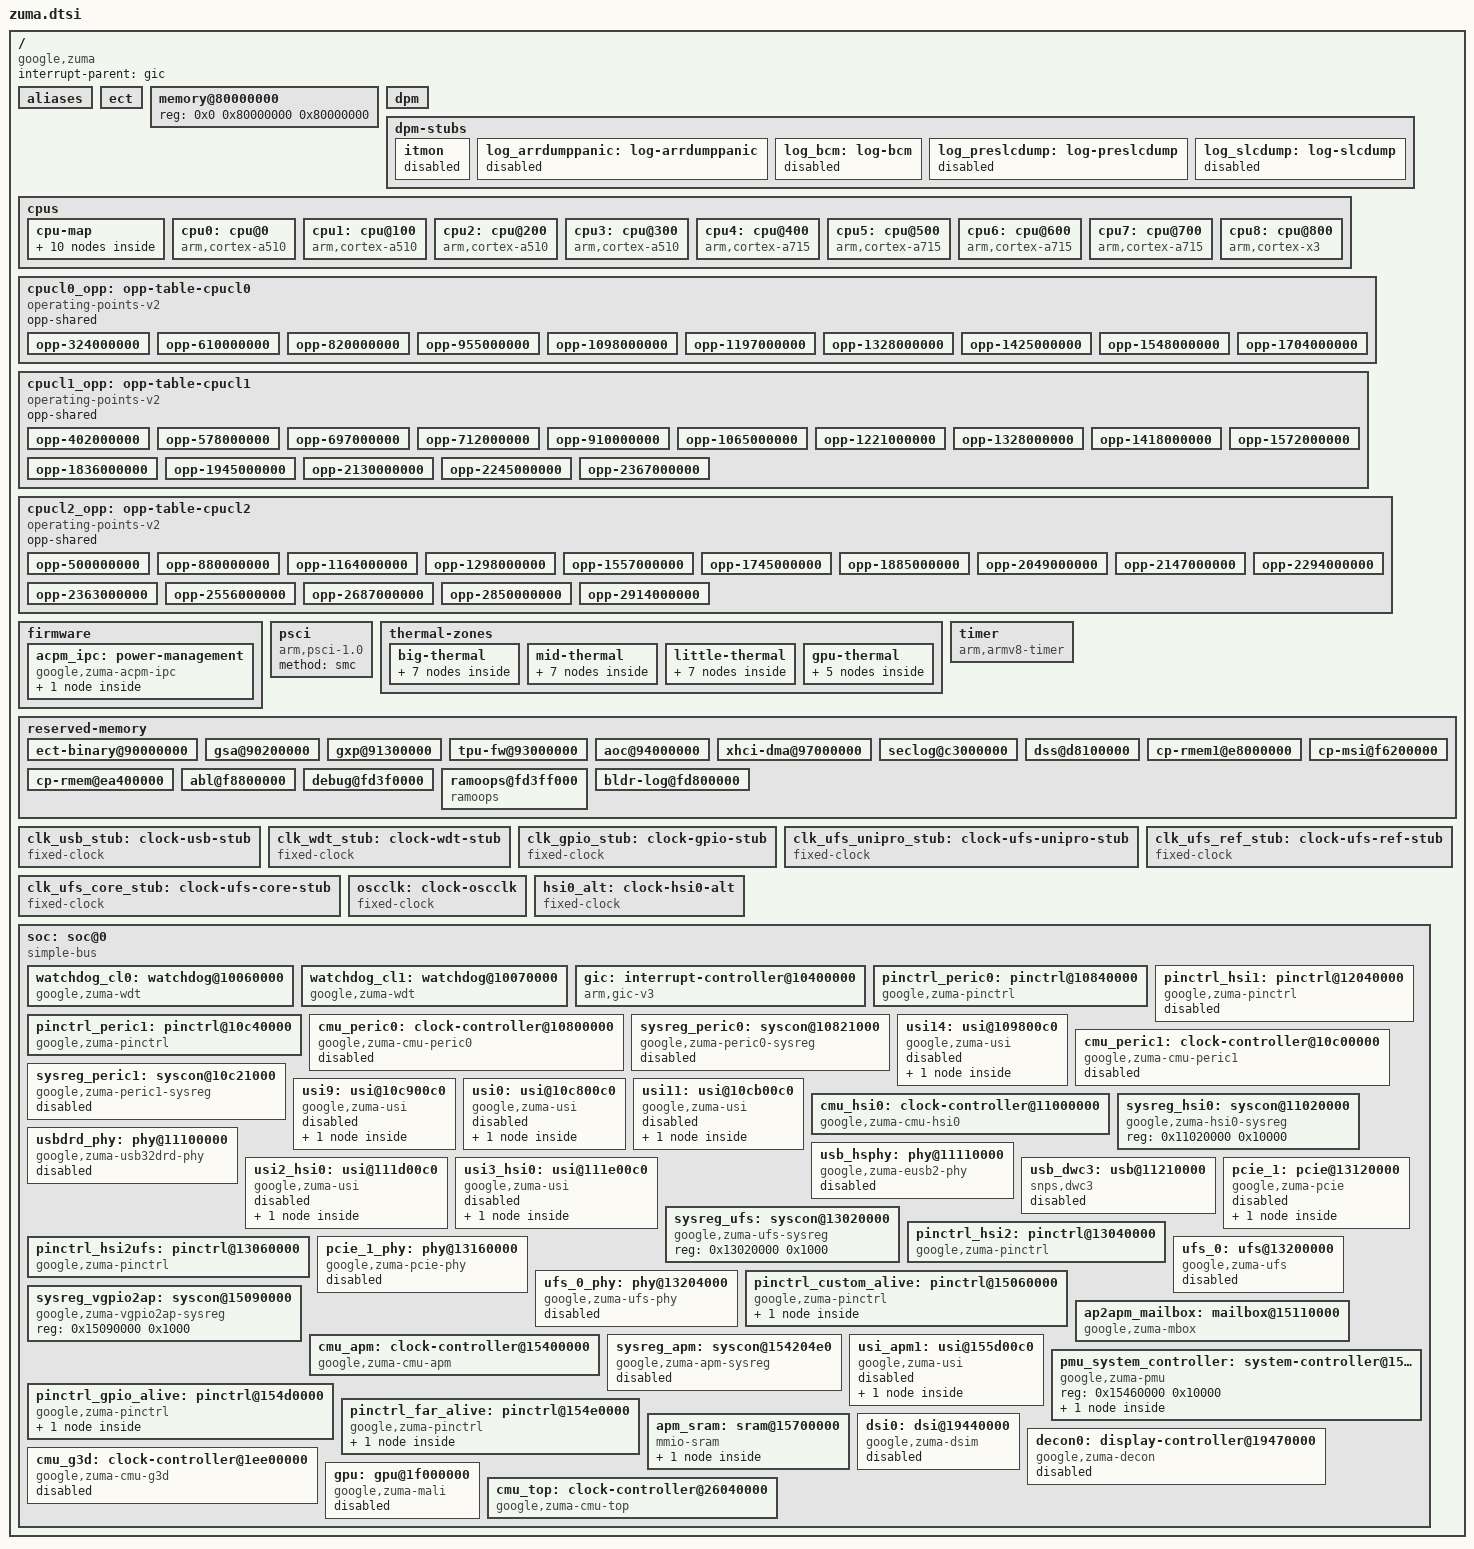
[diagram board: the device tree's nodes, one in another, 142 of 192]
// SPDX-License-Identifier: GPL-2.0-only
/*
 * Google Zuma (Tensor G3) SoC - minimal description for first light.
 *
 * Addresses, interrupts and reservations are the ones a retail Pixel 8 Pro
 * (husky) runs with: its live device tree and Google's GPL zuma tree
 * (android-gs-shusky-6.1-android16). Nothing here is copied from gs101 or
 * gs201. The clock providers describe only the touchscreen SPI's path, and
 * there are no power-domain providers yet: the bootloader leaves what the
 * rest needs running, and the board's bootargs carry clk_ignore_unused and
 * pd_ignore_unused.
 */

#include <dt-bindings/clock/google,zuma.h>
#include <dt-bindings/clock/google,zuma-acpm.h>
#include <dt-bindings/gpio/gpio.h>
#include <dt-bindings/interrupt-controller/arm-gic.h>
#include <dt-bindings/interrupt-controller/irq.h>
#include <dt-bindings/soc/samsung,exynos-usi.h>

/ {
	compatible = "google,zuma";
	#address-cells = <2>;
	#size-cells = <1>;
	interrupt-parent = <&gic>;

	/* The pin controllers are numbered as in Tensor G4's driver data. */
	aliases {
		pinctrl0 = &pinctrl_gpio_alive;
		pinctrl1 = &pinctrl_custom_alive;
		pinctrl2 = &pinctrl_far_alive;
		pinctrl8 = &pinctrl_hsi1;
		pinctrl9 = &pinctrl_hsi2;
		pinctrl10 = &pinctrl_hsi2ufs;
		pinctrl11 = &pinctrl_peric0;
		pinctrl12 = &pinctrl_peric1;
	};

	/*
	 * Required by the Pixel bootloader (ABL). zuma's stock base DTB
	 * carries the ECT location here rather than an empty node.
	 */
	ect {
		parameter_address = <0x90000000>;
		parameter_size = <0x53000>;
	};

	/*
	 * Stock's base DTB has the first DRAM bank; ABL adds the others
	 * and may update this node rather than create one.
	 */
	memory@80000000 {
		device_type = "memory";
		reg = <0x0 0x80000000 0x80000000>;
	};

	/* Target of the ABL-applied debug-policy (dpm partition) overlay. */
	dpm: dpm { };

	/*
	 * Labels the user-build debug-policy overlay targets besides &dpm
	 * (Google zuma-dpm-user.dtsi): stubs, so it applies to this tree.
	 */
	dpm-stubs {
		itmon: itmon { status = "disabled"; };
		log_arrdumppanic: log-arrdumppanic { status = "disabled"; };
		log_bcm: log-bcm { status = "disabled"; };
		log_preslcdump: log-preslcdump { status = "disabled"; };
		log_slcdump: log-slcdump { status = "disabled"; };
	};

	cpus {
		#address-cells = <1>;
		#size-cells = <0>;

		cpu-map {
			cluster0 {
				core0 { cpu = <&cpu0>; };
				core1 { cpu = <&cpu1>; };
				core2 { cpu = <&cpu2>; };
				core3 { cpu = <&cpu3>; };
				core4 { cpu = <&cpu4>; };
				core5 { cpu = <&cpu5>; };
				core6 { cpu = <&cpu6>; };
				core7 { cpu = <&cpu7>; };
				core8 { cpu = <&cpu8>; };
			};
		};

		/*
		 * Four Cortex-A510, four Cortex-A715 and one Cortex-X3 (MIDR
		 * parts 0xd46, 0xd4d, 0xd4e). Capacities are stock's.
		 */
		cpu0: cpu@0 {
			device_type = "cpu";
			compatible = "arm,cortex-a510";
			reg = <0x000>;
			enable-method = "psci";
			capacity-dmips-mhz = <193>;
			#cooling-cells = <2>;
			clocks = <&acpm_ipc ZUMA_CLK_ACPM_DVFS_CPUCL0>;
		};
		cpu1: cpu@100 {
			device_type = "cpu";
			compatible = "arm,cortex-a510";
			reg = <0x100>;
			enable-method = "psci";
			capacity-dmips-mhz = <193>;
			#cooling-cells = <2>;
			clocks = <&acpm_ipc ZUMA_CLK_ACPM_DVFS_CPUCL0>;
		};
		cpu2: cpu@200 {
			device_type = "cpu";
			compatible = "arm,cortex-a510";
			reg = <0x200>;
			enable-method = "psci";
			capacity-dmips-mhz = <193>;
			#cooling-cells = <2>;
			clocks = <&acpm_ipc ZUMA_CLK_ACPM_DVFS_CPUCL0>;
		};
		cpu3: cpu@300 {
			device_type = "cpu";
			compatible = "arm,cortex-a510";
			reg = <0x300>;
			enable-method = "psci";
			capacity-dmips-mhz = <193>;
			#cooling-cells = <2>;
			clocks = <&acpm_ipc ZUMA_CLK_ACPM_DVFS_CPUCL0>;
		};
		cpu4: cpu@400 {
			device_type = "cpu";
			compatible = "arm,cortex-a715";
			reg = <0x400>;
			enable-method = "psci";
			capacity-dmips-mhz = <927>;
			#cooling-cells = <2>;
			clocks = <&acpm_ipc ZUMA_CLK_ACPM_DVFS_CPUCL1>;
		};
		cpu5: cpu@500 {
			device_type = "cpu";
			compatible = "arm,cortex-a715";
			reg = <0x500>;
			enable-method = "psci";
			capacity-dmips-mhz = <927>;
			#cooling-cells = <2>;
			clocks = <&acpm_ipc ZUMA_CLK_ACPM_DVFS_CPUCL1>;
		};
		cpu6: cpu@600 {
			device_type = "cpu";
			compatible = "arm,cortex-a715";
			reg = <0x600>;
			enable-method = "psci";
			capacity-dmips-mhz = <927>;
			#cooling-cells = <2>;
			clocks = <&acpm_ipc ZUMA_CLK_ACPM_DVFS_CPUCL1>;
		};
		cpu7: cpu@700 {
			device_type = "cpu";
			compatible = "arm,cortex-a715";
			reg = <0x700>;
			enable-method = "psci";
			capacity-dmips-mhz = <927>;
			#cooling-cells = <2>;
			clocks = <&acpm_ipc ZUMA_CLK_ACPM_DVFS_CPUCL1>;
		};
		cpu8: cpu@800 {
			device_type = "cpu";
			compatible = "arm,cortex-x3";
			reg = <0x800>;
			enable-method = "psci";
			capacity-dmips-mhz = <1024>;
			#cooling-cells = <2>;
			clocks = <&acpm_ipc ZUMA_CLK_ACPM_DVFS_CPUCL2>;
		};
	};

	/*
	 * CPU levels: the ACPM firmware's own DVFS levels, from the ECT that the
	 * bootloader leaves at 0x90000000, up to each cluster's max-freq in
	 * stock's exynos-acme domains (Google's zuma-cpu.dtsi). The levels
	 * above, listed in each table, are left out as stock leaves them.
	 *
	 * The firmware sets the rail voltages from its fused ASV tables, so
	 * there is no opp-microvolt, and the energy model can't be computed
	 * from a power coefficient. opp-microwatt is each level's power in
	 * stock's default energy model (the pixel-em profile in Google's
	 * zuma-b0-ipop.dts, the same in the Pixel 8 Pro's own device tree).
	 *
	 * Stock caps the mid and big clusters at 1945 and 2294 MHz whenever
	 * its battery current limiter (BCL) sees the battery voltage droop
	 * (freq_qos vdroop1/vdroop2/smpl_warn in Google's
	 * zuma-shusky-bcl.dtsi). There is no BCL driver here, so the levels
	 * above those caps are turbo-mode: off until boost is enabled
	 * (/sys/devices/system/cpu/cpufreq/boost).
	 *
	 * Those turbo-mode marks are the Pixel 8 Pro's caps, so the CPUs get
	 * operating-points-v2 in the board file. A board whose BCL caps are
	 * lower needs tables of its own.
	 */
	cpucl0_opp: opp-table-cpucl0 {
		compatible = "operating-points-v2";
		opp-shared;

		opp-324000000 {
			opp-hz = /bits/ 64 <324000000>;
			opp-microwatt = <11000>;
		};

		opp-610000000 {
			opp-hz = /bits/ 64 <610000000>;
			opp-microwatt = <12000>;
		};

		opp-820000000 {
			opp-hz = /bits/ 64 <820000000>;
			opp-microwatt = <19000>;
		};

		opp-955000000 {
			opp-hz = /bits/ 64 <955000000>;
			opp-microwatt = <25000>;
		};

		opp-1098000000 {
			opp-hz = /bits/ 64 <1098000000>;
			opp-microwatt = <31000>;
		};

		opp-1197000000 {
			opp-hz = /bits/ 64 <1197000000>;
			opp-microwatt = <37000>;
		};

		opp-1328000000 {
			opp-hz = /bits/ 64 <1328000000>;
			opp-microwatt = <45000>;
		};

		opp-1425000000 {
			opp-hz = /bits/ 64 <1425000000>;
			opp-microwatt = <57000>;
		};

		opp-1548000000 {
			opp-hz = /bits/ 64 <1548000000>;
			opp-microwatt = <155000>;
		};

		opp-1704000000 {
			opp-hz = /bits/ 64 <1704000000>;
			opp-microwatt = <195000>;
		};

		/* 1785, 1950, 2024, 2098, 2147 and 2253 MHz stay off, as on stock. */
	};

	cpucl1_opp: opp-table-cpucl1 {
		compatible = "operating-points-v2";
		opp-shared;

		opp-402000000 {
			opp-hz = /bits/ 64 <402000000>;
			opp-microwatt = <59000>;
		};

		opp-578000000 {
			opp-hz = /bits/ 64 <578000000>;
			opp-microwatt = <85000>;
		};

		opp-697000000 {
			opp-hz = /bits/ 64 <697000000>;
			opp-microwatt = <106000>;
		};

		opp-712000000 {
			opp-hz = /bits/ 64 <712000000>;
			opp-microwatt = <114000>;
		};

		opp-910000000 {
			opp-hz = /bits/ 64 <910000000>;
			opp-microwatt = <156000>;
		};

		opp-1065000000 {
			opp-hz = /bits/ 64 <1065000000>;
			opp-microwatt = <208000>;
		};

		opp-1221000000 {
			opp-hz = /bits/ 64 <1221000000>;
			opp-microwatt = <266000>;
		};

		opp-1328000000 {
			opp-hz = /bits/ 64 <1328000000>;
			opp-microwatt = <320000>;
		};

		opp-1418000000 {
			opp-hz = /bits/ 64 <1418000000>;
			opp-microwatt = <368000>;
		};

		opp-1572000000 {
			opp-hz = /bits/ 64 <1572000000>;
			opp-microwatt = <449000>;
		};

		opp-1836000000 {
			opp-hz = /bits/ 64 <1836000000>;
			opp-microwatt = <638000>;
		};

		opp-1945000000 {
			opp-hz = /bits/ 64 <1945000000>;
			opp-microwatt = <804000>;
		};

		opp-2130000000 {
			opp-hz = /bits/ 64 <2130000000>;
			opp-microwatt = <1042000>;
			turbo-mode;
		};

		opp-2245000000 {
			opp-hz = /bits/ 64 <2245000000>;
			opp-microwatt = <1272000>;
			turbo-mode;
		};

		opp-2367000000 {
			opp-hz = /bits/ 64 <2367000000>;
			opp-microwatt = <1514000>;
			turbo-mode;
		};

		/* 2450 and 2600 MHz stay off, as on stock. */
	};

	cpucl2_opp: opp-table-cpucl2 {
		compatible = "operating-points-v2";
		opp-shared;

		opp-500000000 {
			opp-hz = /bits/ 64 <500000000>;
			opp-microwatt = <116000>;
		};

		opp-880000000 {
			opp-hz = /bits/ 64 <880000000>;
			opp-microwatt = <213000>;
		};

		opp-1164000000 {
			opp-hz = /bits/ 64 <1164000000>;
			opp-microwatt = <321000>;
		};

		opp-1298000000 {
			opp-hz = /bits/ 64 <1298000000>;
			opp-microwatt = <391000>;
		};

		opp-1557000000 {
			opp-hz = /bits/ 64 <1557000000>;
			opp-microwatt = <535000>;
		};

		opp-1745000000 {
			opp-hz = /bits/ 64 <1745000000>;
			opp-microwatt = <675000>;
		};

		opp-1885000000 {
			opp-hz = /bits/ 64 <1885000000>;
			opp-microwatt = <784000>;
		};

		opp-2049000000 {
			opp-hz = /bits/ 64 <2049000000>;
			opp-microwatt = <1034000>;
		};

		opp-2147000000 {
			opp-hz = /bits/ 64 <2147000000>;
			opp-microwatt = <1145000>;
		};

		opp-2294000000 {
			opp-hz = /bits/ 64 <2294000000>;
			opp-microwatt = <1363000>;
		};

		opp-2363000000 {
			opp-hz = /bits/ 64 <2363000000>;
			opp-microwatt = <1533000>;
			turbo-mode;
		};

		opp-2556000000 {
			opp-hz = /bits/ 64 <2556000000>;
			opp-microwatt = <1911000>;
			turbo-mode;
		};

		opp-2687000000 {
			opp-hz = /bits/ 64 <2687000000>;
			opp-microwatt = <2415000>;
			turbo-mode;
		};

		opp-2850000000 {
			opp-hz = /bits/ 64 <2850000000>;
			opp-microwatt = <3175000>;
			turbo-mode;
		};

		opp-2914000000 {
			opp-hz = /bits/ 64 <2914000000>;
			opp-microwatt = <3714000>;
			turbo-mode;
		};

		/* 2943, 2970 and 3015 MHz stay off, as on stock. */
	};

	firmware {
		acpm_ipc: power-management {
			compatible = "google,zuma-acpm-ipc";
			#clock-cells = <1>;
			mboxes = <&ap2apm_mailbox>;
			shmem = <&apm_sram>;

			acpm_tmu: thermal-sensor {
				compatible = "google,zuma-acpm-tmu";
				#thermal-sensor-cells = <1>;
			};
		};
	};

	psci {
		compatible = "arm,psci-1.0";
		method = "smc";
	};

	thermal-zones {
		/*
		 * The CPU zones throttle their cluster from 80 C and force its
		 * lowest level from 95 C.
		 */
		big-thermal {
			polling-delay-passive = <250>;
			polling-delay = <1000>;
			thermal-sensors = <&acpm_tmu 0>;

			trips {
				big_alert: big-alert {
					temperature = <80000>;
					hysteresis = <5000>;
					type = "passive";
				};

				big_hot: big-hot {
					temperature = <95000>;
					hysteresis = <10000>;
					type = "passive";
				};

				big_crit: big-crit {
					temperature = <105000>;
					hysteresis = <2000>;
					type = "critical";
				};
			};

			cooling-maps {
				map0 {
					trip = <&big_alert>;
					cooling-device = <&cpu8 0xffffffff 0xffffffff>;
				};

				map1 {
					trip = <&big_hot>;
					cooling-device = <&cpu8 14 0xffffffff>;
				};
			};
		};

		mid-thermal {
			polling-delay-passive = <250>;
			polling-delay = <1000>;
			thermal-sensors = <&acpm_tmu 1>;

			trips {
				mid_alert: mid-alert {
					temperature = <80000>;
					hysteresis = <5000>;
					type = "passive";
				};

				mid_hot: mid-hot {
					temperature = <95000>;
					hysteresis = <10000>;
					type = "passive";
				};

				mid_crit: mid-crit {
					temperature = <105000>;
					hysteresis = <2000>;
					type = "critical";
				};
			};

			cooling-maps {
				map0 {
					trip = <&mid_alert>;
					cooling-device = <&cpu4 0xffffffff 0xffffffff>;
				};

				map1 {
					trip = <&mid_hot>;
					cooling-device = <&cpu4 14 0xffffffff>;
				};
			};
		};

		little-thermal {
			polling-delay-passive = <250>;
			polling-delay = <1000>;
			thermal-sensors = <&acpm_tmu 2>;

			trips {
				little_alert: little-alert {
					temperature = <80000>;
					hysteresis = <5000>;
					type = "passive";
				};

				little_hot: little-hot {
					temperature = <95000>;
					hysteresis = <10000>;
					type = "passive";
				};

				little_crit: little-crit {
					temperature = <105000>;
					hysteresis = <2000>;
					type = "critical";
				};
			};

			cooling-maps {
				map0 {
					trip = <&little_alert>;
					cooling-device = <&cpu0 0xffffffff 0xffffffff>;
				};

				map1 {
					trip = <&little_hot>;
					cooling-device = <&cpu0 9 0xffffffff>;
				};
			};
		};

		/*
		 * Below stock's own GPU trips (passive from 100 C, hot at
		 * 115 C).
		 */
		gpu-thermal {
			polling-delay-passive = <1000>;
			polling-delay = <2000>;
			thermal-sensors = <&acpm_tmu 3>;

			trips {
				gpu_alert: gpu-alert {
					temperature = <85000>;
					hysteresis = <5000>;
					type = "passive";
				};

				gpu_crit: gpu-crit {
					temperature = <105000>;
					hysteresis = <2000>;
					type = "critical";
				};
			};

			/* panthor's devfreq cooling: step_wise walks the GPU down its OPPs. */
			cooling-maps {
				map0 {
					trip = <&gpu_alert>;
					cooling-device = <&gpu 0xffffffff 0xffffffff>;
				};
			};
		};
	};

	timer {
		compatible = "arm,armv8-timer";
		interrupts = <GIC_PPI 13 IRQ_TYPE_LEVEL_LOW>,
			     <GIC_PPI 14 IRQ_TYPE_LEVEL_LOW>,
			     <GIC_PPI 11 IRQ_TYPE_LEVEL_LOW>,
			     <GIC_PPI 10 IRQ_TYPE_LEVEL_LOW>;
	};

	/*
	 * Fixed DRAM carve-outs from the live device tree, without the regions
	 * ABL adds itself: pkvm_guest_firmware, sec_dram and sec_pt, and
	 * debug_kinfo_reserved (in stock's base DTB, added by ABL to a tree
	 * without it). Firmware, co-processors or the bootloader own these, so
	 * the kernel must not use them, whether or not a driver for the owner
	 * exists yet.
	 * Stock leaves ect-binary, seclog and the three CP regions mapped for
	 * the drivers that read them; with no such driver here they are
	 * no-map, like the rest, on purpose.
	 * Dynamically placed pools (CMA, GCMA) are left out.
	 */
	reserved-memory {
		#address-cells = <2>;
		#size-cells = <1>;
		ranges;

		ect-binary@90000000 { reg = <0x0 0x90000000 0x60000>; no-map; };
		gsa@90200000 { reg = <0x0 0x90200000 0x400000>; no-map; };
		gxp@91300000 { reg = <0x0 0x91300000 0x1100000>; no-map; };
		tpu-fw@93000000 { reg = <0x0 0x93000000 0x1000000>; no-map; };
		aoc@94000000 { reg = <0x0 0x94000000 0x3000000>; no-map; };
		xhci-dma@97000000 { reg = <0x0 0x97000000 0x400000>; no-map; };
		seclog@c3000000 { reg = <0x0 0xc3000000 0x90000>; no-map; };
		/* debug-snapshot: header through log_s2d_extract */
		dss@d8100000 { reg = <0x0 0xd8100000 0x5f20000>; no-map; };
		cp-rmem1@e8000000 { reg = <0x0 0xe8000000 0x2000000>; no-map; };
		cp-rmem@ea400000 { reg = <0x0 0xea400000 0xc00000>; no-map; };
		cp-msi@f6200000 { reg = <0x0 0xf6200000 0x1000>; no-map; };
		abl@f8800000 { reg = <0x0 0xf8800000 0x1000000>; no-map; };
		debug@fd3f0000 { reg = <0x0 0xfd3f0000 0xe000>; no-map; };
		/*
		 * Stock's ramoops layout. zuma's user-build bootloader does not
		 * keep it across a warm reset (even stock's own console log is
		 * gone after one), so for now this only reserves the region.
		 */
		ramoops@fd3ff000 {
			compatible = "ramoops";
			reg = <0x0 0xfd3ff000 0x400000>;
			console-size = <0x200000>;
			pmsg-size = <0x200000>;
		};
		bldr-log@fd800000 { reg = <0x0 0xfd800000 0x100000>; no-map; };
	};

	/*
	 * Stand-in for CMU_HSI0's USB clocks until zuma has a clock driver.
	 * ABL leaves HSI0 clocked (the DWC3 ID register reads back correctly);
	 * the PHY drivers only need a handle and the 19.2 MHz reference rate.
	 */
	clk_usb_stub: clock-usb-stub {
		compatible = "fixed-clock";
		#clock-cells = <0>;
		clock-frequency = <19200000>;
		clock-output-names = "usb_stub";
	};

	/*
	 * Stand-in for the watchdogs' clocks (zuma has no clock driver yet):
	 * stock runs both counters from the 24.576 MHz oscillator, and ABL
	 * leaves their gates open.
	 */
	clk_wdt_stub: clock-wdt-stub {
		compatible = "fixed-clock";
		#clock-cells = <0>;
		clock-frequency = <24576000>;
		clock-output-names = "wdt_stub";
	};

	/*
	 * Stand-in for the pin controllers' bus clocks (no clock driver yet).
	 * Stock's pin controllers take no clock: ABL leaves them running. The
	 * driver only enables it, so its rate is never used.
	 */
	clk_gpio_stub: clock-gpio-stub {
		compatible = "fixed-clock";
		#clock-cells = <0>;
		clock-frequency = <0>;
		clock-output-names = "gpio_stub";
	};

	/*
	 * Stand-ins for the UFS clocks (no clock driver yet; ABL leaves them
	 * running, as it reads UFS itself). The UniPro clock is stock's
	 * (its driver logs "mclk: 178000000"); the link core clock's rate is
	 * only checked against the driver's range, and it also stands in for
	 * the FMP, bus and sysreg gates; the PHY's reference is the 38.4 MHz
	 * its CAL is written for.
	 */
	clk_ufs_unipro_stub: clock-ufs-unipro-stub {
		compatible = "fixed-clock";
		#clock-cells = <0>;
		clock-frequency = <178000000>;
		clock-output-names = "ufs_unipro_stub";
	};

	clk_ufs_core_stub: clock-ufs-core-stub {
		compatible = "fixed-clock";
		#clock-cells = <0>;
		clock-frequency = <267000000>;
		clock-output-names = "ufs_core_stub";
	};

	clk_ufs_ref_stub: clock-ufs-ref-stub {
		compatible = "fixed-clock";
		#clock-cells = <0>;
		clock-frequency = <38400000>;
		clock-output-names = "ufs_ref_stub";
	};

	oscclk: clock-oscclk {
		compatible = "fixed-clock";
		#clock-cells = <0>;
		clock-frequency = <24576000>;
		clock-output-names = "oscclk";
	};

	/* The CAL's nominal I_CLK_HSI0_ALT rate. */
	hsi0_alt: clock-hsi0-alt {
		compatible = "fixed-clock";
		#clock-cells = <0>;
		clock-frequency = <213000000>;
		clock-output-names = "hsi0-alt";
	};

	soc: soc@0 {
		compatible = "simple-bus";
		#address-cells = <1>;
		#size-cells = <1>;
		/* Registers below 1 GiB, PCIe windows at 0x40000000-0x7fffffff */
		ranges = <0x0 0x0 0x0 0x80000000>;

		/*
		 * ABL hands over with both cluster watchdogs counting (30 s);
		 * without a driver to take them over the phone resets about
		 * 80 s into boot.
		 */
		watchdog_cl0: watchdog@10060000 {
			compatible = "google,zuma-wdt";
			reg = <0x10060000 0x100>;
			interrupts = <GIC_SPI 767 IRQ_TYPE_LEVEL_HIGH>;
			clocks = <&clk_wdt_stub>, <&clk_wdt_stub>;
			clock-names = "watchdog", "watchdog_src";
			samsung,cluster-index = <0>;
			samsung,syscon-phandle = <&pmu_system_controller>;
		};

		watchdog_cl1: watchdog@10070000 {
			compatible = "google,zuma-wdt";
			reg = <0x10070000 0x100>;
			interrupts = <GIC_SPI 768 IRQ_TYPE_LEVEL_HIGH>;
			clocks = <&clk_wdt_stub>, <&clk_wdt_stub>;
			clock-names = "watchdog", "watchdog_src";
			samsung,cluster-index = <1>;
			samsung,syscon-phandle = <&pmu_system_controller>;
		};

		gic: interrupt-controller@10400000 {
			compatible = "arm,gic-v3";
			#interrupt-cells = <3>;
			#address-cells = <0>;
			interrupt-controller;
			reg = <0x10400000 0x10000>,	/* GICD */
			      <0x10440000 0x200000>;	/* GICR, nine CPUs */
			interrupts = <GIC_PPI 9 IRQ_TYPE_LEVEL_HIGH>;
		};

		pinctrl_peric0: pinctrl@10840000 {
			compatible = "google,zuma-pinctrl";
			reg = <0x10840000 0x1000>;
			clocks = <&clk_gpio_stub>;
			clock-names = "pclk";
			interrupts = <GIC_SPI 634 IRQ_TYPE_LEVEL_HIGH>;
		};

		pinctrl_hsi1: pinctrl@12040000 {
			compatible = "google,zuma-pinctrl";
			reg = <0x12040000 0x1000>;
			clocks = <&clk_gpio_stub>;
			clock-names = "pclk";
			interrupts = <GIC_SPI 413 IRQ_TYPE_LEVEL_HIGH>;
			status = "disabled";
		};

		pinctrl_peric1: pinctrl@10c40000 {
			compatible = "google,zuma-pinctrl";
			reg = <0x10c40000 0x1000>;
			clocks = <&clk_gpio_stub>;
			clock-names = "pclk";
			interrupts = <GIC_SPI 649 IRQ_TYPE_LEVEL_HIGH>;
		};

		/* CMU_PERIC0 and USI14, the I2C bus of the rear flash LED. */
		cmu_peric0: clock-controller@10800000 {
			compatible = "google,zuma-cmu-peric0";
			reg = <0x10800000 0x8000>;
			#clock-cells = <1>;
			clocks = <&oscclk>, <&cmu_top CLK_DOUT_PERIC0_NOC>,
				 <&cmu_top CLK_DOUT_PERIC0_IP>;
			clock-names = "oscclk", "bus", "ip";
			status = "disabled";
		};

		sysreg_peric0: syscon@10821000 {
			compatible = "google,zuma-peric0-sysreg", "syscon";
			reg = <0x10821000 0x1000>;
			clocks = <&cmu_peric0 CLK_GOUT_PERIC0_SYSREG>;
			status = "disabled";
		};

		usi14: usi@109800c0 {
			compatible = "google,zuma-usi", "samsung,exynos850-usi";
			reg = <0x109800c0 0x20>;
			clocks = <&cmu_peric0 CLK_GOUT_PERIC0_USI14_PCLK>,
				 <&cmu_peric0 CLK_GOUT_PERIC0_USI14_IPCLK>;
			clock-names = "pclk", "ipclk";
			samsung,sysreg = <&sysreg_peric0 0x28>;
			samsung,mode = <USI_MODE_I2C>;
			#address-cells = <1>;
			#size-cells = <1>;
			ranges;
			status = "disabled";

			hsi2c_14: i2c@10980000 {
				compatible = "google,zuma-hsi2c",
					     "samsung,exynosautov9-hsi2c";
				/* USI control starts at 0xc0; do not claim it twice. */
				reg = <0x10980000 0xc0>;
				interrupts = <GIC_SPI 648 IRQ_TYPE_LEVEL_HIGH>;
				clocks = <&cmu_peric0 CLK_GOUT_PERIC0_USI14_IPCLK>,
					 <&cmu_peric0 CLK_GOUT_PERIC0_USI14_PCLK>;
				clock-names = "hsi2c", "hsi2c_pclk";
				pinctrl-0 = <&hsi2c14_bus>;
				pinctrl-names = "default";
				#address-cells = <1>;
				#size-cells = <0>;
				status = "disabled";
			};
		};

		/*
		 * CMU_PERIC1 and USI11, the I2C bus of the MAX77759 gauge,
		 * charger and Type-C controller. Firmware leaves them running;
		 * board files enable them.
		 */
		cmu_peric1: clock-controller@10c00000 {
			compatible = "google,zuma-cmu-peric1";
			reg = <0x10c00000 0x8000>;
			#clock-cells = <1>;
			clocks = <&oscclk>, <&cmu_top CLK_DOUT_PERIC1_NOC>,
				 <&cmu_top CLK_DOUT_PERIC1_IP>;
			clock-names = "oscclk", "bus", "ip";
			status = "disabled";
		};

		sysreg_peric1: syscon@10c21000 {
			compatible = "google,zuma-peric1-sysreg", "syscon";
			reg = <0x10c21000 0x1000>;
			clocks = <&cmu_peric1 CLK_GOUT_PERIC1_SYSREG>;
			status = "disabled";
		};

		usi9: usi@10c900c0 {
			compatible = "google,zuma-usi", "samsung,exynos850-usi";
			reg = <0x10c900c0 0x20>;
			clocks = <&cmu_peric1 CLK_GOUT_PERIC1_USI9_PCLK>,
				 <&cmu_peric1 CLK_GOUT_PERIC1_USI9_IPCLK>;
			clock-names = "pclk", "ipclk";
			samsung,sysreg = <&sysreg_peric1 0x4>;
			samsung,mode = <USI_MODE_I2C>;
			#address-cells = <1>;
			#size-cells = <1>;
			ranges;
			status = "disabled";

			hsi2c_9: i2c@10c90000 {
				compatible = "google,zuma-hsi2c",
					     "samsung,exynosautov9-hsi2c";
				/* USI control starts at 0xc0; do not claim it twice. */
				reg = <0x10c90000 0xc0>;
				interrupts = <GIC_SPI 657 IRQ_TYPE_LEVEL_HIGH>;
				clocks = <&cmu_peric1 CLK_GOUT_PERIC1_USI9_IPCLK>,
					 <&cmu_peric1 CLK_GOUT_PERIC1_USI9_PCLK>;
				clock-names = "hsi2c", "hsi2c_pclk";
				pinctrl-0 = <&hsi2c9_bus>;
				pinctrl-names = "default";
				#address-cells = <1>;
				#size-cells = <0>;
				status = "disabled";
			};
		};

		/* USI0 on PERIC1: the haptics driver's I2C bus on the 8 Pro. */
		usi0: usi@10c800c0 {
			compatible = "google,zuma-usi", "samsung,exynos850-usi";
			reg = <0x10c800c0 0x20>;
			clocks = <&cmu_peric1 CLK_GOUT_PERIC1_USI0_PCLK>,
				 <&cmu_peric1 CLK_GOUT_PERIC1_USI0_IPCLK>;
			clock-names = "pclk", "ipclk";
			samsung,sysreg = <&sysreg_peric1 0x0>;
			samsung,mode = <USI_MODE_I2C>;
			#address-cells = <1>;
			#size-cells = <1>;
			ranges;
			status = "disabled";

			hsi2c_0: i2c@10c80000 {
				compatible = "google,zuma-hsi2c",
					     "samsung,exynosautov9-hsi2c";
				/* USI control starts at 0xc0; do not claim it twice. */
				reg = <0x10c80000 0xc0>;
				interrupts = <GIC_SPI 656 IRQ_TYPE_LEVEL_HIGH>;
				clocks = <&cmu_peric1 CLK_GOUT_PERIC1_USI0_IPCLK>,
					 <&cmu_peric1 CLK_GOUT_PERIC1_USI0_PCLK>;
				clock-names = "hsi2c", "hsi2c_pclk";
				pinctrl-0 = <&hsi2c0_bus>;
				pinctrl-names = "default";
				#address-cells = <1>;
				#size-cells = <0>;
				status = "disabled";
			};
		};

		usi11: usi@10cb00c0 {
			compatible = "google,zuma-usi", "samsung,exynos850-usi";
			reg = <0x10cb00c0 0x20>;
			clocks = <&cmu_peric1 CLK_GOUT_PERIC1_USI11_PCLK>,
				 <&cmu_peric1 CLK_GOUT_PERIC1_USI11_IPCLK>;
			clock-names = "pclk", "ipclk";
			samsung,sysreg = <&sysreg_peric1 0xc>;
			samsung,mode = <USI_MODE_I2C>;
			#address-cells = <1>;
			#size-cells = <1>;
			ranges;
			status = "disabled";

			hsi2c_11: i2c@10cb0000 {
				compatible = "google,zuma-hsi2c",
					     "samsung,exynosautov9-hsi2c";
				/* USI control starts at 0xc0; do not claim it twice. */
				reg = <0x10cb0000 0xc0>;
				interrupts = <GIC_SPI 659 IRQ_TYPE_LEVEL_HIGH>;
				clocks = <&cmu_peric1 CLK_GOUT_PERIC1_USI11_IPCLK>,
					 <&cmu_peric1 CLK_GOUT_PERIC1_USI11_PCLK>;
				clock-names = "hsi2c", "hsi2c_pclk";
				pinctrl-0 = <&hsi2c11_bus>;
				pinctrl-names = "default";
				#address-cells = <1>;
				#size-cells = <0>;
				status = "disabled";
			};
		};

		cmu_hsi0: clock-controller@11000000 {
			compatible = "google,zuma-cmu-hsi0";
			reg = <0x11000000 0x8000>;
			#clock-cells = <1>;
			clocks = <&oscclk>, <&cmu_top CLK_DOUT_HSI0_NOC>,
				 <&cmu_top CLK_DOUT_HSI0_PERI>, <&hsi0_alt>;
			clock-names = "oscclk", "bus", "peri", "alt";
		};

		sysreg_hsi0: syscon@11020000 {
			compatible = "google,zuma-hsi0-sysreg", "syscon";
			reg = <0x11020000 0x10000>;
		};

		/*
		 * USB control block: Exynos 2200's link registers, with the
		 * eUSB2 PHY below as its high-speed PHY. The USB3/DP combo PHY
		 * (0x11130000) is left alone; the link runs at high speed.
		 */
		usbdrd_phy: phy@11100000 {
			compatible = "google,zuma-usb32drd-phy";
			reg = <0x11100000 0x200>;
			clocks = <&clk_usb_stub>;
			clock-names = "phy";
			#phy-cells = <1>;
			phys = <&usb_hsphy>;
			phy-names = "hs";
			samsung,pmu-syscon = <&pmu_system_controller>;
			status = "disabled";
		};

		/* Synopsys eUSB2 PHY, the same IP and register map as Exynos 2200's. */
		usb_hsphy: phy@11110000 {
			compatible = "google,zuma-eusb2-phy",
				     "samsung,exynos2200-eusb2-phy";
			reg = <0x11110000 0x200>;
			clocks = <&clk_usb_stub>, <&clk_usb_stub>, <&clk_usb_stub>;
			clock-names = "ref", "bus", "ctrl";
			#phy-cells = <0>;
			status = "disabled";
		};

		usi2_hsi0: usi@111d00c0 {
			compatible = "google,zuma-usi", "samsung,exynos850-usi";
			reg = <0x111d00c0 0x20>;
			clocks = <&cmu_hsi0 CLK_GOUT_HSI0_USI2_PCLK>,
				 <&cmu_hsi0 CLK_GOUT_HSI0_USI2_IP>;
			clock-names = "pclk", "ipclk";
			samsung,sysreg = <&sysreg_hsi0 0x101c>;
			samsung,mode = <USI_MODE_SPI>;
			#address-cells = <1>;
			#size-cells = <1>;
			ranges;
			status = "disabled";

			spi20: spi@111d0000 {
				compatible = "google,zuma-spi", "google,gs101-spi";
				/* USI control starts at 0xc0; do not claim it twice. */
				reg = <0x111d0000 0xc0>;
				interrupts = <GIC_SPI 408 IRQ_TYPE_LEVEL_HIGH>;
				clocks = <&cmu_hsi0 CLK_GOUT_HSI0_USI2_PCLK>,
					 <&cmu_hsi0 CLK_GOUT_HSI0_USI2_IP>;
				clock-names = "spi", "spi_busclk0";
				#address-cells = <1>;
				#size-cells = <0>;
				status = "disabled";
			};
		};

		/*
		 * USI3 on HSI0: the SPI of the Pixel 8 Pro's GNSS receiver (Google's
		 * spi_21). Same layout as USI2 above.
		 */
		usi3_hsi0: usi@111e00c0 {
			compatible = "google,zuma-usi", "samsung,exynos850-usi";
			reg = <0x111e00c0 0x20>;
			clocks = <&cmu_hsi0 CLK_GOUT_HSI0_USI3_PCLK>,
				 <&cmu_hsi0 CLK_GOUT_HSI0_USI3_IP>;
			clock-names = "pclk", "ipclk";
			samsung,sysreg = <&sysreg_hsi0 0x1020>;
			samsung,mode = <USI_MODE_SPI>;
			#address-cells = <1>;
			#size-cells = <1>;
			ranges;
			status = "disabled";

			spi21: spi@111e0000 {
				compatible = "google,zuma-spi", "google,gs101-spi";
				/* USI control starts at 0xc0; do not claim it twice. */
				reg = <0x111e0000 0xc0>;
				interrupts = <GIC_SPI 409 IRQ_TYPE_LEVEL_HIGH>;
				clocks = <&cmu_hsi0 CLK_GOUT_HSI0_USI3_PCLK>,
					 <&cmu_hsi0 CLK_GOUT_HSI0_USI3_IP>;
				clock-names = "spi", "spi_busclk0";
				#address-cells = <1>;
				#size-cells = <0>;
				status = "disabled";
			};
		};

		/*
		 * The DWC3 controller, in peripheral mode as on stock (which
		 * wraps it in Google's exynos9-dwusb glue). On a normal boot
		 * ABL leaves the eUSB2 PHY off, so the core's soft reset only
		 * completes once the PHY above supplies its UTMI clock. The
		 * Samsung eUSB2 repeater on I2C (0x3e) has no driver yet.
		 */
		usb_dwc3: usb@11210000 {
			compatible = "snps,dwc3";
			reg = <0x11210000 0x10000>;
			interrupts = <GIC_SPI 402 IRQ_TYPE_LEVEL_HIGH>;
			phys = <&usbdrd_phy 0>;
			phy-names = "usb2-phy";
			dr_mode = "peripheral";
			maximum-speed = "high-speed";
			snps,dis_u2_susphy_quirk;
			snps,dis_u3_susphy_quirk;
			status = "disabled";
		};

		sysreg_ufs: syscon@13020000 {
			compatible = "google,zuma-ufs-sysreg", "syscon";
			reg = <0x13020000 0x1000>;
		};

		pinctrl_hsi2: pinctrl@13040000 {
			compatible = "google,zuma-pinctrl";
			reg = <0x13040000 0x1000>;
			clocks = <&clk_gpio_stub>;
			clock-names = "pclk";
			interrupts = <GIC_SPI 432 IRQ_TYPE_LEVEL_HIGH>;
		};

		pinctrl_hsi2ufs: pinctrl@13060000 {
			compatible = "google,zuma-pinctrl";
			reg = <0x13060000 0x1000>;
			clocks = <&clk_gpio_stub>;
			clock-names = "pclk";
			interrupts = <GIC_SPI 433 IRQ_TYPE_LEVEL_HIGH>;
		};

		/*
		 * The Wi-Fi chip's controller (stock's pcie_1, ch-num 1): one
		 * Gen3 lane, at the addresses of stock's pcie@13120000. Its
		 * interrupts are its legacy INTx; stock's MSI lines are unused.
		 */
		pcie_1: pcie@13120000 {
			compatible = "google,zuma-pcie";
			reg = <0x13120000 0x1400>,
			      <0x13400000 0x381000>,
			      <0x60ffe000 0x2000>;
			reg-names = "elbi", "dbi", "config";
			#address-cells = <3>;
			#size-cells = <2>;
			device_type = "pci";
			ranges = <0x82000000 0x0 0x60000000 0x60000000 0x0 0xff0000>;
			bus-range = <0x00 0xff>;
			interrupts = <GIC_SPI 439 IRQ_TYPE_LEVEL_HIGH>;
			#interrupt-cells = <1>;
			interrupt-map-mask = <0 0 0 7>;
			interrupt-map = <0 0 0 1 &pcie_1_intc 1>,
					<0 0 0 2 &pcie_1_intc 2>,
					<0 0 0 3 &pcie_1_intc 3>,
					<0 0 0 4 &pcie_1_intc 4>;
			phys = <&pcie_1_phy>;
			phy-names = "pcie";
			pinctrl-0 = <&pcie1_clkreq>, <&pcie1_perst>;
			pinctrl-names = "default";
			reset-gpios = <&gph3 0 GPIO_ACTIVE_LOW>;
			num-lanes = <1>;
			max-link-speed = <3>;
			status = "disabled";

			pcie_1_intc: legacy-interrupt-controller {
				#address-cells = <0>;
				interrupt-controller;
				#interrupt-cells = <1>;
			};
		};

		pcie_1_phy: phy@13160000 {
			compatible = "google,zuma-pcie-phy";
			reg = <0x13160000 0x3000>,
			      <0x13140000 0x5000>,
			      <0x13121400 0x10>,
			      <0x13150000 0xd000>,
			      <0x13130000 0x5000>;
			reg-names = "pma", "pcs", "rst", "udbg", "soc";
			samsung,pmu-syscon = <&pmu_system_controller 0x3ec8>;
			#phy-cells = <0>;
			status = "disabled";
		};

		ufs_0: ufs@13200000 {
			compatible = "google,zuma-ufs", "google,zumapro-ufs";
			reg = <0x13200000 0x200>,
			      <0x13201100 0x2000>,
			      <0x13280000 0x8000>,
			      <0x132a0000 0xa014>;
			reg-names = "hci", "vs_hci", "unipro", "ufsp";
			interrupts = <GIC_SPI 466 IRQ_TYPE_LEVEL_HIGH>;
			clocks = <&clk_ufs_core_stub>, <&clk_ufs_unipro_stub>,
				 <&clk_ufs_core_stub>, <&clk_ufs_core_stub>,
				 <&clk_ufs_core_stub>, <&clk_ufs_core_stub>;
			clock-names = "core_clk", "sclk_unipro_main", "fmp",
				      "aclk", "pclk", "sysreg";
			dma-coherent;
			freq-table-hz = <0 0>, <0 0>, <0 0>, <0 0>, <0 0>, <0 0>;
			phys = <&ufs_0_phy>;
			phy-names = "ufs-phy";
			pinctrl-0 = <&ufs_rst_n &ufs_refclk_out>;
			pinctrl-names = "default";
			samsung,sysreg = <&sysreg_ufs 0x710>;
			status = "disabled";
		};

		ufs_0_phy: phy@13204000 {
			compatible = "google,zuma-ufs-phy", "google,zumapro-ufs-phy";
			reg = <0x13204000 0x4000>;
			reg-names = "phy-pma";
			samsung,pmu-syscon = <&pmu_system_controller>;
			#phy-cells = <0>;
			clocks = <&clk_ufs_ref_stub>;
			clock-names = "ref_clk";
			status = "disabled";
		};

		pinctrl_custom_alive: pinctrl@15060000 {
			compatible = "google,zuma-pinctrl";
			reg = <0x15060000 0x1000>;
			clocks = <&cmu_apm CLK_GOUT_APM_GPIO_CUSTOM_ALIVE>;
			clock-names = "pclk";

			wakeup-interrupt-controller {
				compatible = "google,zuma-wakeup-eint",
					     "google,zumapro-wakeup-eint";
			};
		};

		/* Latches the S2MPG14 PMIC's in-band interrupt (GIC SPI 74). */
		sysreg_vgpio2ap: syscon@15090000 {
			compatible = "google,zuma-vgpio2ap-sysreg", "syscon";
			reg = <0x15090000 0x1000>;
		};

		ap2apm_mailbox: mailbox@15110000 {
			compatible = "google,zuma-mbox", "google,gs101-mbox";
			reg = <0x15110000 0x1000>;
			clocks = <&cmu_apm CLK_GOUT_APM_MAILBOX_AP>;
			clock-names = "pclk";
			interrupts = <GIC_SPI 80 IRQ_TYPE_LEVEL_HIGH>;
			#mbox-cells = <0>;
		};

		cmu_apm: clock-controller@15400000 {
			compatible = "google,zuma-cmu-apm";
			reg = <0x15400000 0x8000>;
			#clock-cells = <1>;
			clocks = <&oscclk>;
			clock-names = "oscclk";
		};

		sysreg_apm: syscon@154204e0 {
			compatible = "google,zuma-apm-sysreg", "syscon";
			/* Only the USI mode selectors. */
			reg = <0x154204e0 0x8>;
			clocks = <&cmu_apm CLK_GOUT_APM_SYSREG>;
			status = "disabled";
		};

		/* The APM's USI1, the UART of the Bluetooth chip on the 8 Pro. */
		usi_apm1: usi@155d00c0 {
			compatible = "google,zuma-usi", "samsung,exynos850-usi";
			reg = <0x155d00c0 0x20>;
			clocks = <&cmu_apm CLK_GOUT_APM_USI1_UART_PCLK>,
				 <&cmu_apm CLK_GOUT_APM_USI1_UART_IPCLK>;
			clock-names = "pclk", "ipclk";
			samsung,sysreg = <&sysreg_apm 0x4>;
			samsung,mode = <USI_MODE_UART>;
			samsung,clkreq-on;
			#address-cells = <1>;
			#size-cells = <1>;
			ranges;
			status = "disabled";

			uart18: serial@155d0000 {
				compatible = "google,zuma-uart", "google,gs101-uart";
				reg = <0x155d0000 0xc0>;
				interrupts = <GIC_SPI 71 IRQ_TYPE_LEVEL_HIGH>;
				clocks = <&cmu_apm CLK_GOUT_APM_USI1_UART_PCLK>,
					 <&cmu_apm CLK_GOUT_APM_USI1_UART_IPCLK>;
				clock-names = "uart", "clk_uart_baud0";
				samsung,uart-fifosize = <256>;
				status = "disabled";
			};
		};

		/* Writes go through EL3 (SMC), as on gs101. */
		pmu_system_controller: system-controller@15460000 {
			compatible = "google,zuma-pmu";
			reg = <0x15460000 0x10000>;
			#clock-cells = <1>;

			/*
			 * The bootloader reads the reboot reason from SYSIP_DAT0,
			 * where stock's pixel-reboot driver writes it
			 * (reboot-cmd-offset 0x810), with gs101's and gs201's values.
			 */
			reboot-mode {
				compatible = "syscon-reboot-mode";
				offset = <0x0810>; /* SYSIP_DAT0 */
				mode-bootloader = <0xfc>;
				mode-fastboot = <0xfa>;
				mode-recovery = <0xff>;
			};
		};

		pinctrl_gpio_alive: pinctrl@154d0000 {
			compatible = "google,zuma-pinctrl";
			reg = <0x154d0000 0x1000>;
			clocks = <&clk_gpio_stub>;
			clock-names = "pclk";

			wakeup-interrupt-controller {
				compatible = "google,zuma-wakeup-eint",
					     "google,zumapro-wakeup-eint";
			};
		};

		pinctrl_far_alive: pinctrl@154e0000 {
			compatible = "google,zuma-pinctrl";
			reg = <0x154e0000 0x1000>;
			clocks = <&cmu_apm CLK_GOUT_APM_GPIO_FAR_ALIVE>;
			clock-names = "pclk";

			wakeup-interrupt-controller {
				compatible = "google,zuma-wakeup-eint",
					     "google,zumapro-wakeup-eint";
			};
		};

		apm_sram: sram@15700000 {
			compatible = "mmio-sram";
			reg = <0x15700000 0x58000>;
			clocks = <&cmu_apm CLK_GOUT_APM_INTMEM_ACLK>;
			#address-cells = <1>;
			#size-cells = <1>;
			ranges = <0x0 0x15700000 0x58000>;
			no-memory-wc;

			/* The APM firmware's window, as one block. */
			firmware-sram@0 {
				reg = <0x0 0x58000>;
			};
		};

		dsi0: dsi@19440000 {
			compatible = "google,zuma-dsim", "google,gs201-dsim";
			reg = <0x19440000 0x300>, <0x19460100 0x700>,
			      <0x19460000 0x100>;
			reg-names = "dsi", "dphy", "dphy-extra";
			interrupts = <GIC_SPI 252 IRQ_TYPE_LEVEL_HIGH>;
			#address-cells = <1>;
			#size-cells = <0>;
			status = "disabled";
		};

		/* Scans out what the bootloader set up; no panel or clock control. */
		decon0: display-controller@19470000 {
			compatible = "google,zuma-decon";
			reg = <0x19470000 0x2000>, <0x19900000 0x1000>;
			reg-names = "main", "dma";
			interrupts = <GIC_SPI 243 IRQ_TYPE_LEVEL_HIGH>,
				     <GIC_SPI 242 IRQ_TYPE_LEVEL_HIGH>,
				     <GIC_SPI 241 IRQ_TYPE_LEVEL_HIGH>;
			interrupt-names = "frame_start", "frame_done", "extra";
			status = "disabled";
		};

		/* The bootloader leaves G3D powered; there's no power domain yet. */
		cmu_g3d: clock-controller@1ee00000 {
			compatible = "google,zuma-cmu-g3d";
			reg = <0x1ee00000 0x8000>;
			#clock-cells = <1>;
			clocks = <&oscclk>, <&cmu_top CLK_DOUT_G3D_NOCD>,
				 <&cmu_top CLK_DOUT_G3D_GLB>,
				 <&cmu_top CLK_DOUT_G3D_SWITCH>;
			clock-names = "oscclk", "bus", "glb", "switch";
			status = "disabled";
		};

		gpu: gpu@1f000000 {
			compatible = "google,zuma-mali", "arm,mali-valhall-csf";
			reg = <0x1f000000 0x480000>;
			interrupts = <GIC_SPI 347 IRQ_TYPE_LEVEL_HIGH>,
				     <GIC_SPI 348 IRQ_TYPE_LEVEL_HIGH>,
				     <GIC_SPI 346 IRQ_TYPE_LEVEL_HIGH>;
			interrupt-names = "job", "mmu", "gpu";
			clocks = <&cmu_g3d CLK_GOUT_G3D_CORE>,
				 <&cmu_g3d CLK_GOUT_G3D_COREGROUP>,
				 <&cmu_g3d CLK_GOUT_G3D_STACKS>;
			clock-names = "core", "coregroup", "stacks";
			#cooling-cells = <2>;
			status = "disabled";
		};

		cmu_top: clock-controller@26040000 {
			compatible = "google,zuma-cmu-top";
			reg = <0x26040000 0x8000>;
			#clock-cells = <1>;
			clocks = <&oscclk>;
			clock-names = "oscclk";
		};
	};
};

#include "zuma-pinctrl.dtsi"
